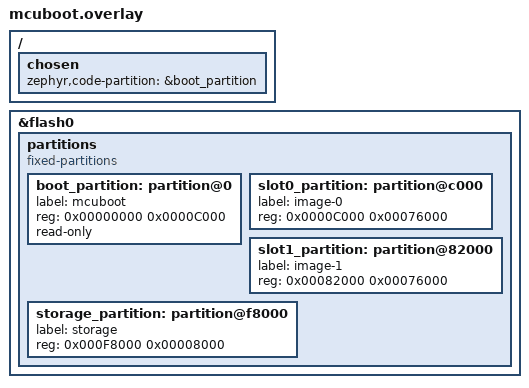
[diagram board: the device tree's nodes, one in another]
/*
 * Auto-discovered by sysbuild for the "mcuboot" child image (see
 * ExternalZephyrProject_Add's sysbuild/<image>.overlay lookup in
 * share/sysbuild/cmake/modules/sysbuild_extensions.cmake). This REPLACES
 * mcuboot's own default overlay
 * (bootloader/mcuboot/boot/zephyr/app.overlay) rather than adding to it,
 * so it has to carry that overlay's one line (the code-partition chosen
 * node) itself, on top of the same partition layout the app image uses
 * (node/boards/mcuboot_partitions.overlay) - both images need to agree on
 * where boot_partition/slot0_partition/slot1_partition physically are.
 */

/ {
	chosen {
		zephyr,code-partition = &boot_partition;
	};
};

&flash0 {
	/delete-node/ partitions;

	partitions {
		compatible = "fixed-partitions";
		#address-cells = <1>;
		#size-cells = <1>;

		boot_partition: partition@0 {
			label = "mcuboot";
			reg = <0x00000000 0x0000C000>;
			read-only;
		};

		slot0_partition: partition@c000 {
			label = "image-0";
			reg = <0x0000C000 0x00076000>;
		};

		slot1_partition: partition@82000 {
			label = "image-1";
			reg = <0x00082000 0x00076000>;
		};

		storage_partition: partition@f8000 {
			label = "storage";
			reg = <0x000F8000 0x00008000>;
		};
	};
};
